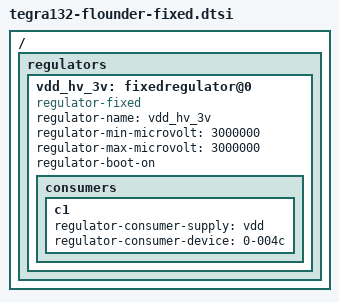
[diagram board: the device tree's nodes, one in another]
#include <dt-bindings/gpio/tegra-gpio.h>
#include "tegra132-flounder-fixed-common.dtsi"

/ {
	regulators {
		vdd_hv_3v: fixedregulator@0 {
			compatible = "regulator-fixed";
			regulator-name = "vdd_hv_3v";
			regulator-min-microvolt = <3000000>;
			regulator-max-microvolt = <3000000>;
			regulator-boot-on;
			consumers {
				c1 {
					regulator-consumer-supply = "vdd";
					regulator-consumer-device = "0-004c";
				};
			};
		};
	};
};
